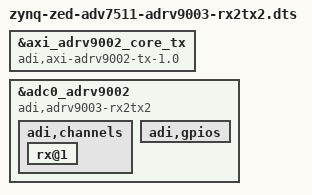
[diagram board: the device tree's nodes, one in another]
// SPDX-License-Identifier: GPL-2.0
/*
 * Analog Devices ADRV9002
 *
 * hdl_project: <adrv9001/zed>
 * board_revision: <1.0>
 *
 * Copyright (C) 2022 Analog Devices Inc.
 */
/dts-v1/;

#include "zynq-zed.dtsi"
#include "zynq-zed-adv7511.dtsi"
#include "zynq-adrv9002-rx2tx2.dtsi"

&axi_adrv9002_core_tx {
	/* just have TX1 */
	compatible = "adi,axi-adrv9002-tx-1.0";
};

&adc0_adrv9002 {
	compatible = "adi,adrv9003-rx2tx2";

	/* delete tx2 and ORX2 gpio */
	adi,channels {
		/delete-node/ tx@1;
		rx@1 {
			/delete-property/ orx-gpios;
		};
	};

	adi,gpios {
		/delete-node/ gpio@1;
	};
};
